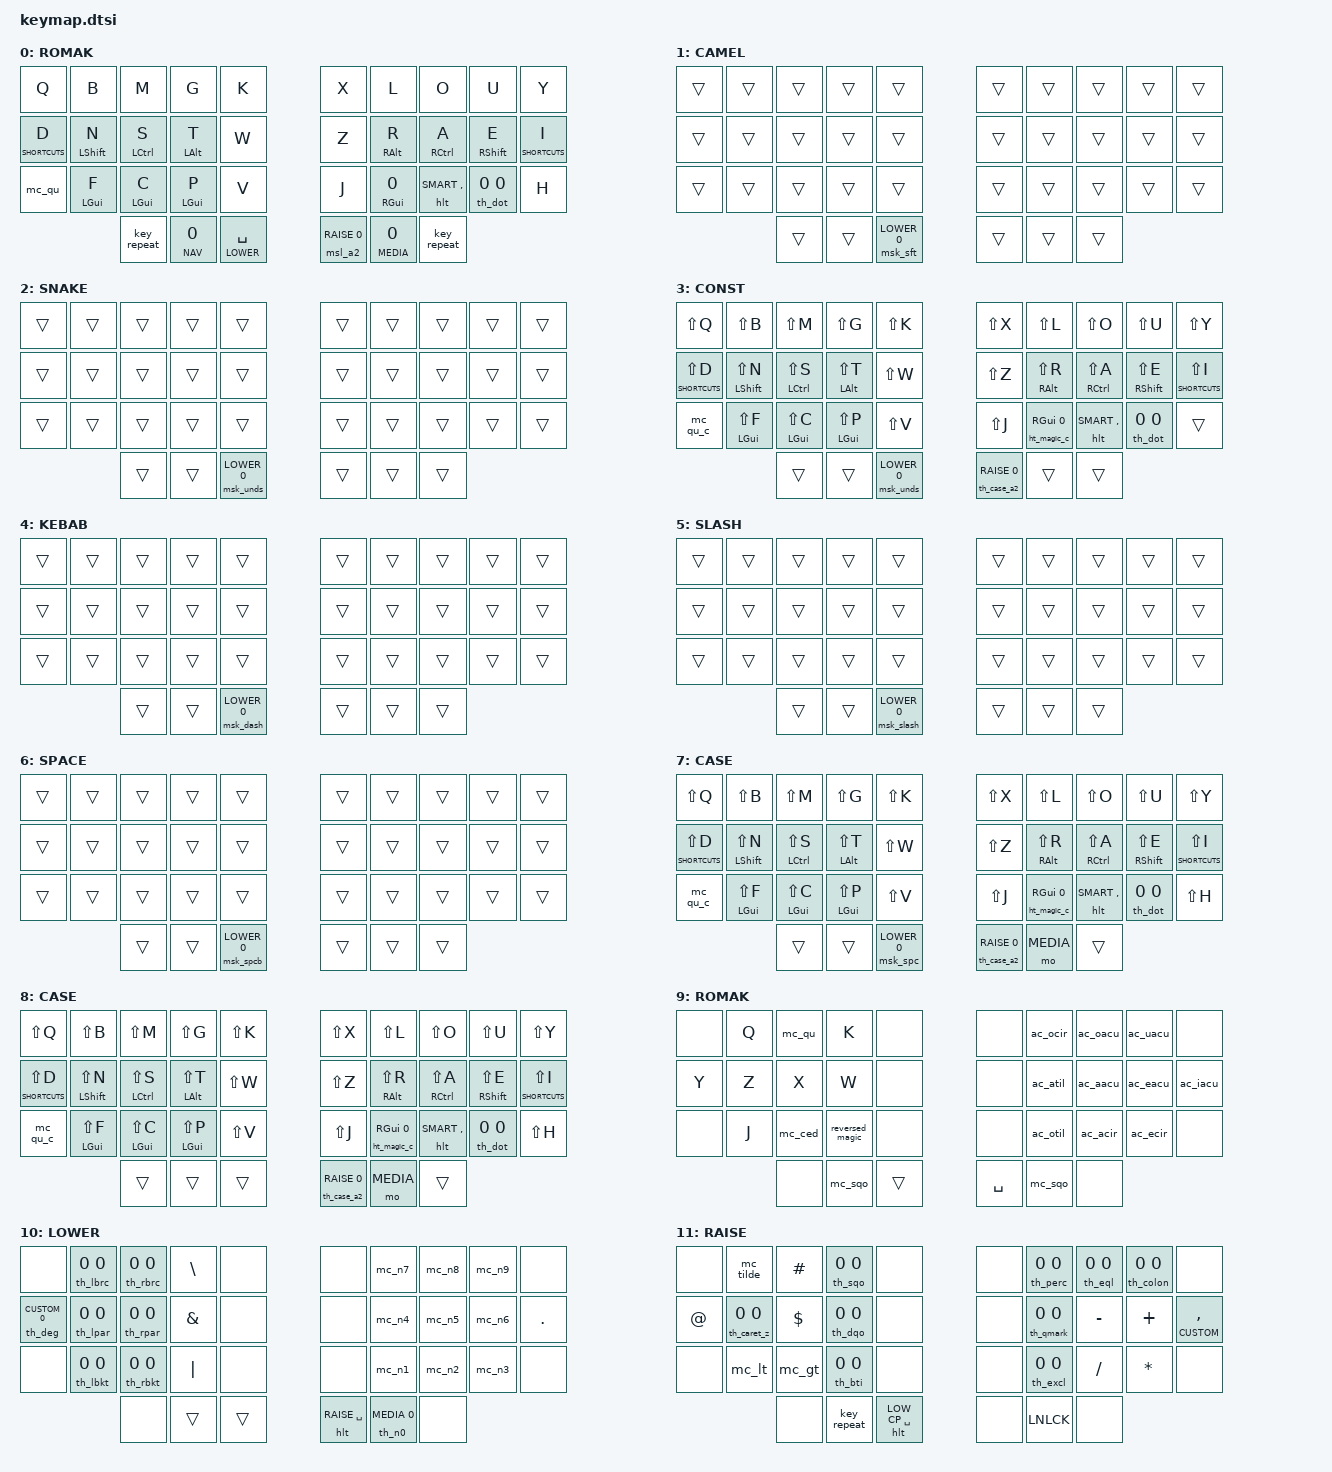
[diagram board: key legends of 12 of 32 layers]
/*
*
* Copyright (c) 2022 Rafael Romão
* SPDX-License-Identifier: MIT
*
*/

#include "keycodes.h"
#include "config.dtsi"

#include "../features/mouse.dtsi"
#include "../features/accents.dtsi"
#include "../features/smart.dtsi"
#include "../features/magic.dtsi"
#include "../features/symbols.dtsi"
#include "../features/shortcuts.dtsi"
#include "../features/combos.dtsi"
#include "../features/leader.dtsi"
#if __has_include("../secret.dtsi")
#include "../secret.dtsi"
#endif

/ {
        keymap {
                compatible = "zmk,keymap";
                default_layer {
                     display-name = "ROMAK";
                     bindings = <
   &kp Q               &kp B               &kp M               &kp G               &kp K               &kp X               &kp L               &kp O               &kp U               &kp Y
   &lt SHORTCUTS D     &mt LSHFT N         &mt LCTRL S         &mt LALT T          &kp W               &kp Z               &mt RALT R          &mt RCTRL A         &mt RSHFT E         &lt SHORTCUTS I      
   &mc_qu              &mt LGUI F          &mt LGUI C          &mt LGUI P          &kp V               &kp J               &ht_magic RGUI 0    &hlt SMART COMMA    &th_dot 0 0         &kp H
                                           &key_repeat         &ht_repeat NAV 0    &ltn LOWER SPACE    &msl_a2 RAISE 0     &ht_shift MEDIA 0   &key_repeat
                        >;
                };

                camel_case_layer {
                     display-name = "CAMEL";
                     bindings = <
   &trans              &trans              &trans              &trans              &trans              &trans              &trans              &trans              &trans              &trans    
   &trans              &trans              &trans              &trans              &trans              &trans              &trans              &trans              &trans              &trans  
   &trans              &trans              &trans              &trans              &trans              &trans              &trans              &trans              &trans              &trans 
                                           &trans              &trans              &msk_sft LOWER 0    &trans              &trans              &trans
                           >;
                };
                snake_case_layer {
                     display-name = "SNAKE";
                     bindings = <
   &trans              &trans              &trans              &trans              &trans              &trans              &trans              &trans              &trans              &trans    
   &trans              &trans              &trans              &trans              &trans              &trans              &trans              &trans              &trans              &trans  
   &trans              &trans              &trans              &trans              &trans              &trans              &trans              &trans              &trans              &trans 
                                           &trans              &trans              &msk_unds LOWER 0   &trans              &trans              &trans
                           >;
                };
                constant_layer {
                     display-name = "CONST";
                     bindings = <
   &kp LS(Q)           &kp LS(B)           &kp LS(M)           &kp LS(G)           &kp LS(K)           &kp LS(X)           &kp LS(L)           &kp LS(O)           &kp LS(U)           &kp LS(Y)
   &lt SHORTCUTS LS(D) &mt LSHFT LS(N)     &mt LCTRL LS(S)     &mt LALT LS(T)      &kp LS(W)           &kp LS(Z)           &mt RALT LS(R)      &mt RCTRL LS(A)     &mt RSHFT LS(E)     &lt SHORTCUTS LS(I) 
   &mc_qu_c            &mt LGUI LS(F)      &mt LGUI LS(C)      &mt LGUI LS(P)      &kp LS(V)           &kp LS(J)           &ht_magic_c RGUI 0  &hlt SMART COMMA    &th_dot 0 0         &trans
                                           &trans              &trans              &msk_unds LOWER 0   &th_case_a2 RAISE 0 &trans              &trans
                           >;
                };
                kebab_case_layer {
                     display-name = "KEBAB";
                     bindings = <
   &trans              &trans              &trans              &trans              &trans              &trans              &trans              &trans              &trans              &trans    
   &trans              &trans              &trans              &trans              &trans              &trans              &trans              &trans              &trans              &trans  
   &trans              &trans              &trans              &trans              &trans              &trans              &trans              &trans              &trans              &trans 
                                           &trans              &trans              &msk_dash LOWER 0   &trans              &trans              &trans
                           >;
                };
                slash_case_layer {
                     display-name = "SLASH";
                     bindings = <
   &trans              &trans              &trans              &trans              &trans              &trans              &trans              &trans              &trans              &trans    
   &trans              &trans              &trans              &trans              &trans              &trans              &trans              &trans              &trans              &trans  
   &trans              &trans              &trans              &trans              &trans              &trans              &trans              &trans              &trans              &trans 
                                           &trans              &trans              &msk_slash LOWER 0  &trans              &trans              &trans
                           >;
                };
                spacing_layer {
                     display-name = "SPACE";
                     bindings = <
   &trans              &trans              &trans              &trans              &trans              &trans              &trans              &trans              &trans              &trans    
   &trans              &trans              &trans              &trans              &trans              &trans              &trans              &trans              &trans              &trans  
   &trans              &trans              &trans              &trans              &trans              &trans              &trans              &trans              &trans              &trans 
                                           &trans              &trans              &msk_spcb LOWER 0   &trans              &trans              &trans
                           >;
                };
                capsword_layer {
                     display-name = "CASE";
                     bindings = <
   &kp LS(Q)           &kp LS(B)           &kp LS(M)           &kp LS(G)           &kp LS(K)           &kp LS(X)           &kp LS(L)           &kp LS(O)           &kp LS(U)           &kp LS(Y)
   &lt SHORTCUTS LS(D) &mt LSHFT LS(N)     &mt LCTRL LS(S)     &mt LALT LS(T)      &kp LS(W)           &kp LS(Z)           &mt RALT LS(R)      &mt RCTRL LS(A)     &mt RSHFT LS(E)     &lt SHORTCUTS LS(I) 
   &mc_qu_c            &mt LGUI LS(F)      &mt LGUI LS(C)      &mt LGUI LS(P)      &kp LS(V)           &kp LS(J)           &ht_magic_c RGUI 0  &hlt SMART COMMA    &th_dot 0 0         &kp LS(H)
                                           &trans              &trans              &msk_spc LOWER 0    &th_case_a2 RAISE 0 &mo MEDIA           &trans
                        >;
                };
                capsline_layer {
                     display-name = "CASE";
                     bindings = <
   &kp LS(Q)           &kp LS(B)           &kp LS(M)           &kp LS(G)           &kp LS(K)           &kp LS(X)           &kp LS(L)           &kp LS(O)           &kp LS(U)           &kp LS(Y)
   &lt SHORTCUTS LS(D) &mt LSHFT LS(N)     &mt LCTRL LS(S)     &mt LALT LS(T)      &kp LS(W)           &kp LS(Z)           &mt RALT LS(R)      &mt RCTRL LS(A)     &mt RSHFT LS(E)     &lt SHORTCUTS LS(I) 
   &mc_qu_c            &mt LGUI LS(F)      &mt LGUI LS(C)      &mt LGUI LS(P)      &kp LS(V)           &kp LS(J)           &ht_magic_c RGUI 0  &hlt SMART COMMA    &th_dot 0 0         &kp LS(H)
                                           &trans              &trans              &trans              &th_case_a2 RAISE 0 &mo MEDIA           &trans
                           >;
                };



                alpha2_layer {
                     display-name = "ROMAK";
                     bindings = <
   &none               &kp Q               &mc_qu              &kp K               &none               &none               &ac_ocir            &ac_oacu            &ac_uacu            &none
   &kp Y               &kp Z               &kp X               &kp W               &none               &none               &ac_atil            &ac_aacu            &ac_eacu            &ac_iacu 
   &none               &kp J               &mc_ced             &reversed_magic     &none               &none               &ac_otil            &ac_acir            &ac_ecir            &none 
                                           &none               &mc_sqo             &trans              &kp SPACE           &mc_sqo             &none
                           >;
                };



                lower_layer {
                     display-name = "LOWER";
                     bindings = <
   &none               &th_lbrc 0 0        &th_rbrc 0 0        &kp BSLH            &none               &none               &mc_n7              &mc_n8              &mc_n9              &none
   &th_deg CUSTOM 0    &th_lpar 0 0        &th_rpar 0 0        &kp AMPS            &none               &none               &mc_n4              &mc_n5              &mc_n6              &kp DOT  
   &none               &th_lbkt 0 0        &th_rbkt 0 0        &kp PIPE            &none               &none               &mc_n1              &mc_n2              &mc_n3              &none 
                                           &none               &trans              &trans              &hlt RAISE SPACE    &th_n0 MEDIA 0      &none 
                           >;
                };
                raise_layer {
                     display-name = "RAISE";
                     bindings = <
   &none               &mc_tilde           &kp HASH            &th_sqo 0 0         &none               &none               &th_perc 0 0        &th_eql 0 0         &th_colon 0 0       &none
   &kp AT              &th_caret_z 0 0     &kp DOLLAR          &th_dqo 0 0         &none               &none               &th_qmark 0 0       &kp MINUS           &kp PLUS            &lt CUSTOM COMMA
   &none               &mc_lt              &mc_gt              &th_bti 0 0         &none               &none               &th_excl 0 0        &kp SLASH           &kp STAR            &none 
                                           &none               &key_repeat         &hlt LOW_CP SPACE   &none               &kp LNLCK            &none        
                           >;
                };



                sentence_case_layer {
                     display-name = "CASE";
                     bindings = <
   &trans              &trans              &trans              &trans              &trans              &trans              &trans              &trans              &trans              &trans    
   &trans              &trans              &trans              &trans              &trans              &trans              &trans              &trans              &trans              &trans  
   &trans              &trans              &trans              &trans              &trans              &trans              &trans              &trans              &trans              &trans 
                                           &trans              &trans              &th_sp_ns LOWER 0   &trans              &th_nsen MEDIA 0    &trans
                           >;
                };
                sentence_case_ext_layer {
                     display-name = "CASE";
                     bindings = <
   &kp RS(Q)           &kp RS(B)           &kp RS(M)           &kp RS(G)           &kp RS(K)           &kp RS(X)           &kp RS(L)           &kp RS(O)           &kp RS(U)           &kp RS(Y) 
   &kp RS(D)           &mt LSHFT RS(N)     &mt LCTRL RS(S)     &mt LALT RS(T)      &kp RS(W)           &kp RS(Z)           &mt RALT RS(R)      &mt RCTRL RS(A)     &mt RSHFT RS(E)     &kp RS(I) 
   &mc_qu_s            &mt LGUI RS(F)      &mt LGUI RS(C)      &mt LGUI RS(P)      &kp RS(V)           &kp RS(J)           &ht_magic_c RGUI 0  &hlt SMART COMMA    &th_dot 0 0         &kp RS(H) 
                                           &trans              &th_cancel NAV 0    &th_sp_ns LOW_CP 0  &msl RAI_CP SFT_A2  &th_nsen MEDIA 0    &trans
                           >;
                };



                ccedil_layer {
                     display-name = "Ç EXT";
                     bindings = <
   &none               &none               &none               &none               &none               &none               &none               &trans              &trans              &none     
   &none               &none               &none               &mc_aotil           &none               &none               &ac_atil            &trans              &none               &none   
   &none               &none               &none               &mc_otiles          &none               &none               &ac_otil            &trans              &trans              &none  
                                           &none               &trans              &trans              &trans              &trans              &none
                           >;
                };
                shifted_alpha2_layer {
                     display-name = "ROMAK";
                     bindings = <
   &none               &kp RS(Q)           &mc_qu_s            &kp RS(K)           &none               &none               &ac_ocir_s          &ac_oacu_s          &ac_uacu_s          &none
   &kp RS(Y)           &kp RS(Z)           &kp RS(X)           &kp RS(W)           &none               &none               &ac_atil_s          &ac_aacu_s          &ac_eacu_s          &ac_iacu_s 
   &none               &kp RS(J)           &mc_ced_s           &reversed_magic_c   &none               &none               &ac_otil_s          &ac_acir_s          &ac_ecir_s          &none  
                                           &none               &mc_sqo             &trans              &kp SPACE           &mc_sqo             &none 
                           >;
                };
                case_alpha2_layer {
                     display-name = "CASE";
                     bindings = <
   &none               &kp LS(Q)           &mc_qu_c            &kp LS(K)           &none               &none               &ac_ocir_c          &ac_oacu_c          &ac_uacu_c          &none
   &kp LS(Y)           &kp LS(Z)           &kp LS(X)           &kp LS(W)           &none               &none               &ac_atil_c          &ac_aacu_c          &ac_eacu_c          &ac_iacu_c 
   &none               &kp LS(J)           &mc_ced_c           &reversed_magic_c   &none               &none               &ac_otil_c          &ac_acir_c          &ac_ecir_c          &none 
                                           &none               &mc_sqo_c           &trans              &kp SPACE           &mc_sqo_c           &none 
                           >;
                };
                case_ccedil_layer {
                     display-name = "CASE";
                     bindings = <
   &none               &none               &none               &none               &none               &none               &none               &trans              &trans              &none     
   &none               &none               &none               &mc_aotil_c         &none               &none               &ac_atil_c          &trans              &none               &none   
   &none               &none               &none               &mc_otiles_c        &none               &none               &ac_otil_c          &trans              &trans              &none 
                                           &none               &trans              &trans              &trans              &trans              &none 
                           >;
                };



                shortcuts_layer {
                     display-name = "SHORTS";
                     bindings = <
   &none               &kp ESC             &mc_files           &mc_preview         &none               &none               &mc_selw            &kp ENTER           &kp ESC             &none    
   &none               &th_zoom RGUI 0     &mc_app_swapper     &th_tabs LGUI 0     &none               &none               &mc_seln            &mm_down_minus      &mm_up_plus         &none
   &none               &mc_term            &mc_calc            &mc_apps            &none               &none               &mc_selh            &ht_ref_clo_z0 0 0  &mc_clip            &none 
                                           &none               &mo FUN             &lt CUSTOM SPACE    &lt CUSTOM SPACE    &mo NAV             &none 
                           >;
                };
                shortcuts_ext_1_layer {
                     display-name = "SHORTS";
                     bindings = <
   &trans              &trans              &trans              &trans              &trans              &trans              &mc_ext_sel         &trans              &trans              &trans    
   &trans              &trans              &trans              &trans              &trans              &trans              &th_ext_sel LALT 0  &trans              &trans              &trans  
   &trans              &trans              &trans              &trans              &trans              &trans              &trans              &trans              &trans              &trans 
                                           &trans              &trans              &trans              &trans              &trans              &trans
                           >;
                };
                shortcuts_ext_2_layer {
                     display-name = "SHORTS";
                     bindings = <
   &trans              &trans              &trans              &trans              &trans              &trans              &trans              &trans              &trans              &trans    
   &trans              &trans              &trans              &trans              &trans              &trans              &trans              &mc_win_b           &mc_win_f           &trans  
   &trans              &trans              &trans              &trans              &trans              &trans              &trans              &mc_app_quit        &trans              &trans 
                                           &trans              &trans              &trans              &trans              &trans              &trans
                           >;
                };
                custom_layer {
                     display-name = "CUSTOM";
                     bindings = <
   &none               &mc_meh_b           &mc_meh_m           &mc_meh_g           &none               &none               &mc_meh_l           &mc_meh_o           &mc_meh_u           &none    
   &mc_meh_d           &mc_meh_n           &mc_meh_s           &mc_meh_t           &none               &none               &mc_meh_r           &mc_meh_a           &mc_meh_e           &mc_meh_i
   &none               &th_meh_f LGUI 0    &th_meh_c LGUI 0    &th_meh_p LGUI 0    &none               &none               &th_meh_h LGUI 0    &th_meh_comm LGUI 0 &th_meh_dot LGUI 0  &none
                                           &none               &th_plain1 NAV 0    &hsk LGUI LGUI      &hsk RGUI RGUI      &th_plain1 NAV 0    &none 
                           >;
                };


                plain1_layer {
                     display-name = "PLAIN";
                     bindings = <
   &kp Q               &kp B               &kp M               &kp G               &kp K               &kp X               &kp L               &kp O               &kp U               &kp Y
   &kp D               &kp N               &kp S               &kp T               &kp W               &kp Z               &kp R               &kp A               &kp E               &kp I 
   &none               &kp F               &kp C               &kp P               &kp V               &kp J               &kp H               &kp COMMA           &kp DOT             &none 
                                           &none               &ht_repeat NAV 0    &lt LOW_CP SPACE    &msl_p2 RAI_CP 0    &ht_sft_p2 MEDIA    &none
                           >;
                };
                plain2_layer {
                     display-name = "PLAIN";
                     bindings = <
   &none               &kp Q               &mc_qu              &kp K               &none               &none               &ac_ocir            &ac_oacu            &ac_uacu            &none
   &kp Y               &kp Z               &kp X               &kp W               &none               &none               &ac_atil            &ac_aacu            &ac_eacu            &ac_iacu 
   &none               &kp J               &mc_ced             &kp V               &none               &none               &ac_otil            &ac_acir            &ac_ecir            &none 
                                           &none               &mc_sqo             &lt LOW_CP SPACE    &lt RAI_CP SPACE    &mc_sqo             &none
                           >;
                };
                shifted_plain2_layer {
                     display-name = "PLAIN";
                     bindings = <
   &none               &kp RS(Q)           &mc_qu_s            &kp RS(K)           &none               &none               &ac_ocir_s          &ac_oacu_s          &ac_uacu_s            &none
   &kp RS(Y)           &kp RS(Z)           &kp RS(X)           &kp RS(W)           &none               &none               &ac_atil_s          &ac_aacu_s          &ac_eacu_s            &ac_iacu_s 
   &none               &kp RS(J)           &mc_ced_s           &kp RS(V)           &none               &none               &ac_otil_s          &ac_acir_s          &ac_ecir_s            &none 
                                           &none               &mc_sqo             &lt LOW_CP SPACE    &lt RAI_CP SPACE    &mc_sqo             &none
                           >;
                };


                navigation_layer {
                     display-name = "NAV";
                     bindings = <
   &none               &mc_word_start      &mc_word_end        &mc_word_next       &none               &none               &kp TAB             &kp ENTER           &kp ESC             &none
   &msl FUN FUN        &kp LSHFT           &kp LCTRL           &kp LALT            &none               &none               &kp LEFT            &kp DOWN            &kp UP              &kp RIGHT
   &none               &kp LGUI            &kp LGUI            &kp LGUI            &none               &none               &kp DEL             &kp HOME            &kp END             &none 
                                           &none               &trans              &bootloader         &kp SPACE           &mo MEDIA           &none 
                        >;
                };



                lower_copy_layer {
                     display-name = "LOWER";
                     bindings = <
   &none               &th_lbrc 0 0        &th_rbrc 0 0        &kp BSLH            &none               &none               &mc_n7              &mc_n8              &mc_n9              &none
   &mc_deg             &th_lpar 0 0        &th_rpar 0 0        &kp AMPS            &none               &none               &mc_n4              &mc_n5              &mc_n6              &kp DOT  
   &none               &th_lbkt 0 0        &th_rbkt 0 0        &kp PIPE            &none               &none               &mc_n1              &mc_n2              &mc_n3              &none 
                                           &none               &trans              &trans              &hlt RAI_CP SPACE   &th_n0 MEDIA 0      &none 
                           >;
                };
                raise_copy_layer {
                     display-name = "RAISE";
                     bindings = <
   &none               &mc_tilde           &kp HASH            &th_sqo 0 0         &none               &none               &th_perc 0 0        &th_eql 0 0         &th_colon 0 0       &none
   &kp AT              &th_caret_z 0 0     &kp DOLLAR          &th_dqo 0 0         &none               &none               &th_qmark 0 0       &kp MINUS           &kp PLUS            &kp STAR  
   &none               &mc_lt              &mc_gt              &th_bti 0 0         &none               &none               &th_excl 0 0        &kp SLASH           &kp STAR            &none 
                                           &none               &key_repeat         &kp SPACE           &kp SPACE           &kp LNLCK           &none 
                           >;
                };



                media_layer {
                    display-name = "MEDIA";
                    bindings = <
   &none               &kp ESC             &mkp LCLK           &mkp RCLK           &none               &none               &kp TAB             &kp ENTER           &kp ESC             &none
   &none               &mmv MOVE_LEFT      &mmv MOVE_UP        &mmv MOVE_RIGHT     &none               &none               &mc_mic             &mt C_MUTE C_VOL_DN &kp C_VOL_UP        &mc_cam
   &none               &msc SCRL_DOWN      &mmv MOVE_DOWN      &msc SCRL_UP        &none               &none               &kp C_PP            &kp C_PREV          &kp C_NEXT          &none 
                                           &none               &mo NAV_F           &kp SPACE           &bootloader         &trans              &none 
                           >;
                };


                functions_layer {
                     display-name = "FUN";
                     bindings = <
   &none               &bt BT_PRV          &bt BT_NXT          &bt BT_CLR          &none               &none               &kp F7              &kp F8              &kp F9              &none 
   &none               &hsk LSHFT LSHFT    &hsk LCTRL LCTRL    &hsk LALT LALT      &none               &none               &kp F4              &kp F5              &kp F6              &none      
   &none               &hsk LGUI LGUI      &hsk LGUI LGUI      &hsk LGUI LGUI      &none               &none               &kp F1              &kp F2              &kp F3              &none
                                           &none               &none               &none               &none               &none               &none
                        >;
                };
                smartcases_layer {
                     display-name = "SMART";
                     bindings = <
   &none               &none               &tc_smart_word      &tc_smart_line      &none               &none               &mc_lock            &none               &none               &none 
   &none               &tc_snake_case      &tc_constant_case   &tc_kebab_case      &none               &none               &kp C_SLEEP         &none               &none               &none      
   &none               &tc_slash_case      &tc_pascal_case     &tc_camel_case      &none               &none               &leader             &none               &none               &none
                                           &none               &none               &mc_comma_space     &none               &none               &none
                        >;
                };


                fixed_navigation_layer {
                     display-name = "NAV";
                     bindings = <
   &none               &mc_word_start      &mc_word_end        &mc_word_next       &none               &none               &kp TAB             &kp ENTER           &kp ESC             &none
   &none               &kp LSHFT           &kp LCTRL           &kp LALT            &none               &none               &kp LEFT            &kp DOWN            &kp UP              &kp RIGHT
   &none               &kp LGUI            &kp LGUI            &kp LGUI            &none               &none               &kp DEL             &kp HOME            &kp END             &none 
                                           &none               &trans              &trans              &kp SPACE           &trans              &none 
                           >;
                };



        };
};
